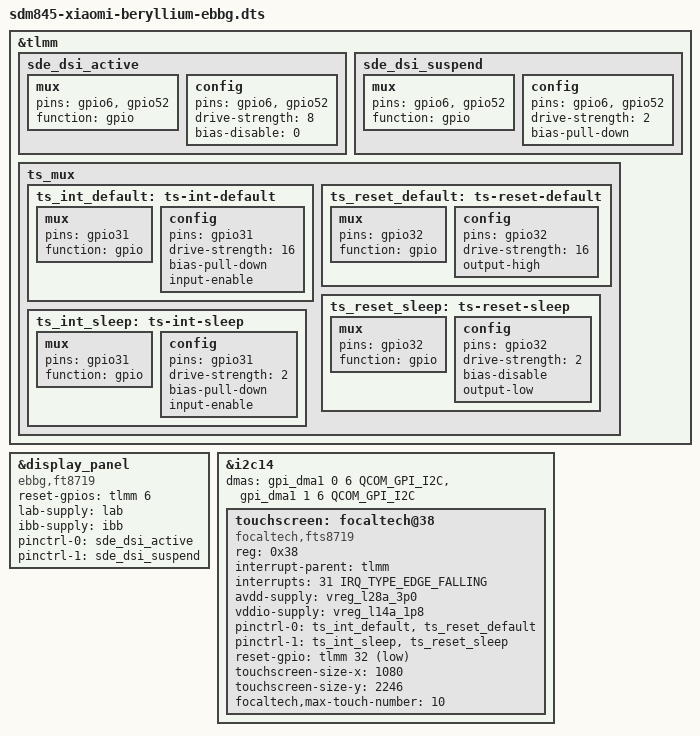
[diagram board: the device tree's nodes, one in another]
// SPDX-License-Identifier: GPL-2.0

/dts-v1/;

#include "sdm845-xiaomi-beryllium-common.dtsi"

&tlmm {

	sde_dsi_active: sde_dsi_active {
		mux {
			pins = "gpio6", "gpio52";
			function = "gpio";
		};

		config {
			pins = "gpio6", "gpio52";
			drive-strength = <8>;   /* 8 mA */
			bias-disable = <0>;   /* no pull */
		};
	};

	sde_dsi_suspend: sde_dsi_suspend {
		mux {
			pins = "gpio6", "gpio52";
			function = "gpio";
		};

		config {
			pins = "gpio6", "gpio52";
			drive-strength = <2>;   /* 2 mA */
			bias-pull-down;		/* PULL DOWN */
		};
	};
};


&display_panel {

	status = "okay";

	reset-gpios = <&tlmm 6 GPIO_ACTIVE_HIGH>;

	lab-supply = <&lab>;
	ibb-supply = <&ibb>;

	pinctrl-names = "panel_active", "panel_suspend";
	pinctrl-0 = <&sde_dsi_active>;
	pinctrl-1 = <&sde_dsi_suspend>;

	compatible = "ebbg,ft8719";

};

&tlmm {
	ts_mux {

		ts_int_default: ts-int-default {
			mux {
				pins = "gpio31";
				function = "gpio";
			};

			config {
				pins = "gpio31";
				drive-strength = <16>;
				bias-pull-down;
				input-enable;
			};
		};

		ts_reset_default: ts-reset-default {
			mux {
				pins = "gpio32";
				function = "gpio";
			};

			config {
				pins = "gpio32";
				drive-strength = <16>;
				output-high;
			};
		};

		ts_reset_sleep: ts-reset-sleep {
			mux {
				pins = "gpio32";
				function = "gpio";
			};

			config {
				pins = "gpio32";
				drive-strength = <2>;
				bias-disable;
				output-low;
			};
		};

		ts_int_sleep: ts-int-sleep {
			mux {
				pins = "gpio31";
				function = "gpio";
			};

			config {
				pins = "gpio31";
				drive-strength = <2>;
				bias-pull-down;
				input-enable;
			};
		};
	};
};

&i2c14 {
	status = "okay";

	dmas =  <&gpi_dma1 0 6 QCOM_GPI_I2C>,
		<&gpi_dma1 1 6 QCOM_GPI_I2C>;
	dma-names = "tx", "rx";

	touchscreen: focaltech@38 {
		compatible = "focaltech,fts8719";
		reg = <0x38>;
		interrupt-parent = <&tlmm>;
		interrupts = <31 IRQ_TYPE_EDGE_FALLING>;

		avdd-supply = <&vreg_l28a_3p0>;
		vddio-supply = <&vreg_l14a_1p8>;

		pinctrl-names = "default", "sleep";
		pinctrl-0 = <&ts_int_default &ts_reset_default>;
		pinctrl-1 = <&ts_int_sleep &ts_reset_sleep>;

		reset-gpio = <&tlmm 32 GPIO_ACTIVE_LOW>;

		touchscreen-size-x = <1080>;
		touchscreen-size-y = <2246>;
		focaltech,max-touch-number = <10>;
	};
};

